AUTOSAR XML (schema 4-3-0)
package /MICROSAR/WdgM_swc/DataTypes
  5 x impl type, all with category=TYPE_REFERENCE:
    WdgM_SupervisedEntityIdType: range raw 0..65535, implementation-data-type=uint16  # Identifier of a supervised entity
    WdgM_CheckpointIdType: range raw 0..65535, implementation-data-type=uint16  # Identifier of a checkpoint
    WdgM_ModeType: range raw 0..255, implementation-data-type=uint8  # Identifier of the Watchdog trigger mode
    WdgM_LocalStatusType: compu {0=WDGM_LOCAL_STATUS_OK, 1=WDGM_LOCAL_STATUS_FAILED, 2=WDGM_LOCAL_STATUS_EXPIRED, 4=WDGM_LOCAL_STATUS_DEACTIVATED}, implementation-data-type=uint8  # Local Monitoring Status of a supervised entity.
    WdgM_GlobalStatusType: compu {0=WDGM_GLOBAL_STATUS_OK, 1=WDGM_GLOBAL_STATUS_FAILED, 2=WDGM_GLOBAL_STATUS_EXPIRED, 3=WDGM_GLOBAL_STATUS_STOPPED, 4=WDGM_GLOBAL_STATUS_DEACTIVATED}, implementation-data-type=uint8  # Global Monitoring Status summarizes all local monitoring statuses of all supervised entities.
package /MICROSAR/WdgM_swc/Interfaces
  client server interface WdgM_AliveSupervision: is-service=true, service-kind=WATCH-DOG-MANAGER
    operation CheckpointReached: possible-error=WdgM_AliveSupervision/E_NOT_OK  # Indicates to the Watchdog Manager that a Checkpoint within a Supervised Entity has been reached.
    error E_NOT_OK: error-code=1
  client server interface WdgM_LocalStatus: is-service=true, service-kind=WATCH-DOG-MANAGER
    operation GetLocalStatus: possible-error=WdgM_LocalStatus/E_NOT_OK  # Returns the supervision status of a supervised entity.
      arg Status: type=WdgM_LocalStatusType, direction=OUT  # Supervision status of the given supervised entity.
    error E_NOT_OK: error-code=1
  client server interface WdgM_General: is-service=true, service-kind=WATCH-DOG-MANAGER
    8 x operation, all with possible-error=WdgM_General/E_NOT_OK:
      GetMode  # Returns the current mode of the Watchdog Manager.
        arg Mode: type=WdgM_ModeType, direction=OUT  # Current mode of the Watchdog Manager.
      GetGlobalStatus  # Returns the global supervision status of the Watchdog Manager.
        arg Status: type=WdgM_GlobalStatusType, direction=OUT  # Global supervision status of the Watchdog Manager.
      GetLocalStatus  # Returns the supervision status of a supervised entity.
        arg SEID: type=WdgM_SupervisedEntityIdType, direction=IN  # Identifier of the supervised entity whose supervision status shall be returned.
        arg Status: type=WdgM_LocalStatusType, direction=OUT  # Supervision status of the given supervised entity.
      PerformReset  # Instructs the Watchdog Manager to cause a watchdog reset.
      SetMode  # Requests a new trigger mode
        arg Mode: type=WdgM_ModeType, direction=IN  # Desired new trigger mode id.
        arg CallerID: type=uint16, direction=IN  # Module ID of the calling module.
      GetFirstExpiredSEID  # Returns the id of that supervised entity which first reached the status WDGM_LOCAL_STATUS_EXPIRED.
        arg SEID: type=WdgM_SupervisedEntityIdType, direction=OUT  # Pointer to a variable that stores the id of the supervised entity.
      ActivateSupervisionEntity  # Activates the supervision of the given supervised entity.
        arg SEID: type=WdgM_SupervisedEntityIdType, direction=IN  # Identifier of the supervised entity whose supervision shall be enabled.
      DeactivateSupervisionEntity  # Deactivates the supervision of the given supervised entity.
        arg SEID: type=WdgM_SupervisedEntityIdType, direction=IN  # Identifier of the supervised entity whose supervision shall be disenabled.
    error E_NOT_OK: error-code=1
package /MICROSAR/WdgM_swc/ComponentTypes
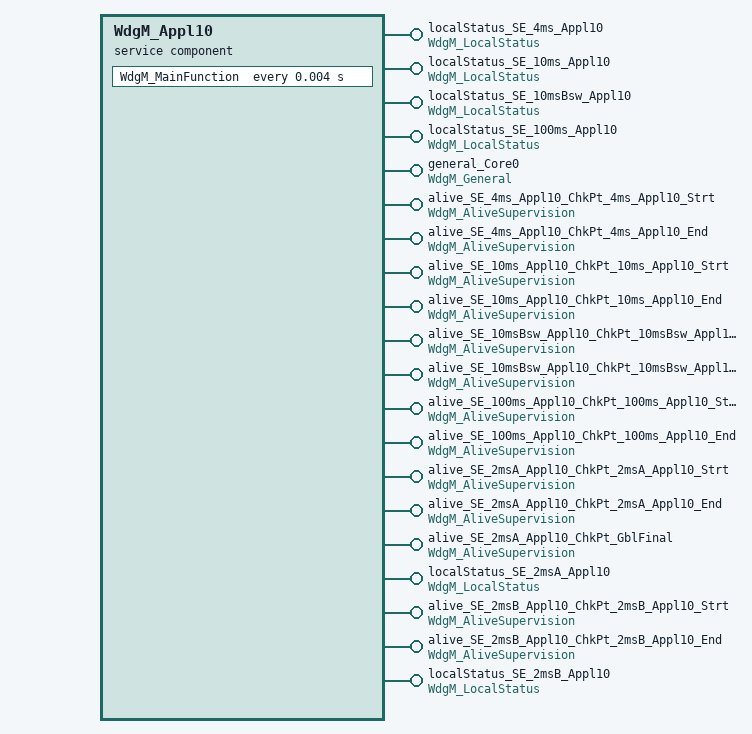
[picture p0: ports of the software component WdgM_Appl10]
  service sw component type WdgM_Appl10: category=SERVICE_COMPONENT
    20 x provide port:
      localStatus_SE_4ms_Appl10: provided-interface=WdgM_LocalStatus  # P-Port Prototype for supervised entity 'SE_4ms_Appl10' with Id '1' for Application 'Appl10' to request the local status.
      localStatus_SE_10ms_Appl10: provided-interface=WdgM_LocalStatus  # P-Port Prototype for supervised entity 'SE_10ms_Appl10' with Id '3' for Application 'Appl10' to request the local status.
      localStatus_SE_10msBsw_Appl10: provided-interface=WdgM_LocalStatus  # P-Port Prototype for supervised entity 'SE_10msBsw_Appl10' with Id '4' for Application 'Appl10' to request the local status.
      localStatus_SE_100ms_Appl10: provided-interface=WdgM_LocalStatus  # P-Port Prototype for supervised entity 'SE_100ms_Appl10' with Id '5' for Application 'Appl10' to request the local status.
      general_Core0: provided-interface=WdgM_General  # General P-Port-Prototype for core 0 (Appl10)
      alive_SE_4ms_Appl10_ChkPt_4ms_Appl10_Strt: provided-interface=WdgM_AliveSupervision  # Alive-P-Port Prototype for supervised entity 'SE_4ms_Appl10' with Id '1' for Application 'Appl10'.
      alive_SE_4ms_Appl10_ChkPt_4ms_Appl10_End: provided-interface=WdgM_AliveSupervision  # Alive-P-Port Prototype for supervised entity 'SE_4ms_Appl10' with Id '1' for Application 'Appl10'.
      alive_SE_10ms_Appl10_ChkPt_10ms_Appl10_Strt: provided-interface=WdgM_AliveSupervision  # Alive-P-Port Prototype for supervised entity 'SE_10ms_Appl10' with Id '3' for Application 'Appl10'.
      alive_SE_10ms_Appl10_ChkPt_10ms_Appl10_End: provided-interface=WdgM_AliveSupervision  # Alive-P-Port Prototype for supervised entity 'SE_10ms_Appl10' with Id '3' for Application 'Appl10'.
      alive_SE_10msBsw_Appl10_ChkPt_10msBsw_Appl10_Strt: provided-interface=WdgM_AliveSupervision  # Alive-P-Port Prototype for supervised entity 'SE_10msBsw_Appl10' with Id '4' for Application 'Appl10'.
      alive_SE_10msBsw_Appl10_ChkPt_10msBsw_Appl10_End: provided-interface=WdgM_AliveSupervision  # Alive-P-Port Prototype for supervised entity 'SE_10msBsw_Appl10' with Id '4' for Application 'Appl10'.
      alive_SE_100ms_Appl10_ChkPt_100ms_Appl10_Strt: provided-interface=WdgM_AliveSupervision  # Alive-P-Port Prototype for supervised entity 'SE_100ms_Appl10' with Id '5' for Application 'Appl10'.
      alive_SE_100ms_Appl10_ChkPt_100ms_Appl10_End: provided-interface=WdgM_AliveSupervision  # Alive-P-Port Prototype for supervised entity 'SE_100ms_Appl10' with Id '5' for Application 'Appl10'.
      alive_SE_2msA_Appl10_ChkPt_2msA_Appl10_Strt: provided-interface=WdgM_AliveSupervision  # Alive-P-Port Prototype for supervised entity 'SE_2msA_Appl10' with Id '0' for Application 'Appl10'.
      alive_SE_2msA_Appl10_ChkPt_2msA_Appl10_End: provided-interface=WdgM_AliveSupervision  # Alive-P-Port Prototype for supervised entity 'SE_2msA_Appl10' with Id '0' for Application 'Appl10'.
      alive_SE_2msA_Appl10_ChkPt_GblFinal: provided-interface=WdgM_AliveSupervision  # Alive-P-Port Prototype for supervised entity 'SE_2msA_Appl10' with Id '0' for Application 'Appl10'.
      localStatus_SE_2msA_Appl10: provided-interface=WdgM_LocalStatus  # P-Port Prototype for supervised entity 'SE_2msA_Appl10' with Id '0' for Application 'Appl10' to request the local status.
      alive_SE_2msB_Appl10_ChkPt_2msB_Appl10_Strt: provided-interface=WdgM_AliveSupervision  # Alive-P-Port Prototype for supervised entity 'SE_2msB_Appl10' with Id '0' for Application 'Appl10'.
      alive_SE_2msB_Appl10_ChkPt_2msB_Appl10_End: provided-interface=WdgM_AliveSupervision  # Alive-P-Port Prototype for supervised entity 'SE_2msB_Appl10' with Id '0' for Application 'Appl10'.
      localStatus_SE_2msB_Appl10: provided-interface=WdgM_LocalStatus  # P-Port Prototype for supervised entity 'SE_2msB_Appl10' with Id '0' for Application 'Appl10' to request the local status.
    behavior WdgM_Appl10InternalBehavior: handle-termination-and-restart=NO-SUPPORT
      timing event Timer_WdgM_MainFunction: start-on-event=WdgM_MainFunction, period=0.004
      27 x operation invoked event:
        OpEventGetLocalStatus_GetLocalStatus_localStatus_SE_4ms_Appl10: start-on-event=WdgM_Appl10InternalBehavior/GetLocalStatus, operation=localStatus_SE_4ms_Appl10.GetLocalStatus
        OpEventGetLocalStatus_GetLocalStatus_localStatus_SE_10ms_Appl10: start-on-event=WdgM_Appl10InternalBehavior/GetLocalStatus, operation=localStatus_SE_10ms_Appl10.GetLocalStatus
        OpEventGetLocalStatus_GetLocalStatus_localStatus_SE_10msBsw_Appl10: start-on-event=WdgM_Appl10InternalBehavior/GetLocalStatus, operation=localStatus_SE_10msBsw_Appl10.GetLocalStatus
        OpEventGetLocalStatus_GetLocalStatus_localStatus_SE_100ms_Appl10: start-on-event=WdgM_Appl10InternalBehavior/GetLocalStatus, operation=localStatus_SE_100ms_Appl10.GetLocalStatus
        OpEventGetLocalStatus_GetLocalStatus_general_Core0: start-on-event=WdgM_Appl10InternalBehavior/GetLocalStatus, operation=general_Core0.GetLocalStatus
        OpEventGetMode_GetMode_general_Core0: start-on-event=GetMode, operation=general_Core0.GetMode
        OpEventGetGlobalStatus_GetGlobalStatus_general_Core0: start-on-event=GetGlobalStatus, operation=general_Core0.GetGlobalStatus
        OpEventPerformReset_PerformReset_general_Core0: start-on-event=PerformReset, operation=general_Core0.PerformReset
        OpEventSetMode_SetMode_general_Core0: start-on-event=SetMode, operation=general_Core0.SetMode
        OpEventGetFirstExpiredSEID_GetFirstExpiredSEID_general_Core0: start-on-event=GetFirstExpiredSEID, operation=general_Core0.GetFirstExpiredSEID
        OpEventCheckpointReached_CheckpointReached_alive_SE_4ms_Appl10_ChkPt_4ms_Appl10_Strt: start-on-event=WdgM_Appl10InternalBehavior/CheckpointReached, operation=alive_SE_4ms_Appl10_ChkPt_4ms_Appl10_Strt.CheckpointReached
        OpEventCheckpointReached_CheckpointReached_alive_SE_4ms_Appl10_ChkPt_4ms_Appl10_End: start-on-event=WdgM_Appl10InternalBehavior/CheckpointReached, operation=alive_SE_4ms_Appl10_ChkPt_4ms_Appl10_End.CheckpointReached
        OpEventCheckpointReached_CheckpointReached_alive_SE_10ms_Appl10_ChkPt_10ms_Appl10_Strt: start-on-event=WdgM_Appl10InternalBehavior/CheckpointReached, operation=alive_SE_10ms_Appl10_ChkPt_10ms_Appl10_Strt.CheckpointReached
        OpEventCheckpointReached_CheckpointReached_alive_SE_10ms_Appl10_ChkPt_10ms_Appl10_End: start-on-event=WdgM_Appl10InternalBehavior/CheckpointReached, operation=alive_SE_10ms_Appl10_ChkPt_10ms_Appl10_End.CheckpointReached
        OpEventCheckpointReached_CheckpointReached_alive_SE_10msBsw_Appl10_ChkPt_10msBsw_Appl10_Strt: start-on-event=WdgM_Appl10InternalBehavior/CheckpointReached, operation=alive_SE_10msBsw_Appl10_ChkPt_10msBsw_Appl10_Strt.CheckpointReached
        OpEventCheckpointReached_CheckpointReached_alive_SE_10msBsw_Appl10_ChkPt_10msBsw_Appl10_End: start-on-event=WdgM_Appl10InternalBehavior/CheckpointReached, operation=alive_SE_10msBsw_Appl10_ChkPt_10msBsw_Appl10_End.CheckpointReached
        OpEventCheckpointReached_CheckpointReached_alive_SE_100ms_Appl10_ChkPt_100ms_Appl10_Strt: start-on-event=WdgM_Appl10InternalBehavior/CheckpointReached, operation=alive_SE_100ms_Appl10_ChkPt_100ms_Appl10_Strt.CheckpointReached
        OpEventCheckpointReached_CheckpointReached_alive_SE_100ms_Appl10_ChkPt_100ms_Appl10_End: start-on-event=WdgM_Appl10InternalBehavior/CheckpointReached, operation=alive_SE_100ms_Appl10_ChkPt_100ms_Appl10_End.CheckpointReached
        OpEventCheckpointReached_CheckpointReached_alive_SE_2msA_Appl10_ChkPt_2msA_Appl10_Strt: start-on-event=WdgM_Appl10InternalBehavior/CheckpointReached, operation=alive_SE_2msA_Appl10_ChkPt_2msA_Appl10_Strt.CheckpointReached
        OpEventCheckpointReached_CheckpointReached_alive_SE_2msA_Appl10_ChkPt_2msA_Appl10_End: start-on-event=WdgM_Appl10InternalBehavior/CheckpointReached, operation=alive_SE_2msA_Appl10_ChkPt_2msA_Appl10_End.CheckpointReached
        OpEventCheckpointReached_CheckpointReached_alive_SE_2msA_Appl10_ChkPt_GblFinal: start-on-event=WdgM_Appl10InternalBehavior/CheckpointReached, operation=alive_SE_2msA_Appl10_ChkPt_GblFinal.CheckpointReached
        OpEventGetLocalStatus_GetLocalStatus_localStatus_SE_2msA_Appl10: start-on-event=WdgM_Appl10InternalBehavior/GetLocalStatus, operation=localStatus_SE_2msA_Appl10.GetLocalStatus
        OpEventCheckpointReached_CheckpointReached_alive_SE_2msB_Appl10_ChkPt_2msB_Appl10_Strt: start-on-event=WdgM_Appl10InternalBehavior/CheckpointReached, operation=alive_SE_2msB_Appl10_ChkPt_2msB_Appl10_Strt.CheckpointReached
        OpEventCheckpointReached_CheckpointReached_alive_SE_2msB_Appl10_ChkPt_2msB_Appl10_End: start-on-event=WdgM_Appl10InternalBehavior/CheckpointReached, operation=alive_SE_2msB_Appl10_ChkPt_2msB_Appl10_End.CheckpointReached
        OpEventGetLocalStatus_GetLocalStatus_localStatus_SE_2msB_Appl10: start-on-event=WdgM_Appl10InternalBehavior/GetLocalStatus, operation=localStatus_SE_2msB_Appl10.GetLocalStatus
        OpEventActivateSupervisionEntity_ActivateSupervisionEntity_general_Core0: start-on-event=ActivateSupervisionEntity, operation=general_Core0.ActivateSupervisionEntity
        OpEventDeactivateSupervisionEntity_DeactivateSupervisionEntity_general_Core0: start-on-event=DeactivateSupervisionEntity, operation=general_Core0.DeactivateSupervisionEntity
      port-api-options:
        {enable-take-address=true, indirect-api=false, port-defined-argument-value{value=1, value-type=WdgM_SupervisedEntityIdType}, port=localStatus_SE_4ms_Appl10}
        {enable-take-address=true, indirect-api=false, port-defined-argument-value{value=3, value-type=WdgM_SupervisedEntityIdType}, port=localStatus_SE_10ms_Appl10}
        {enable-take-address=true, indirect-api=false, port-defined-argument-value{value=4, value-type=WdgM_SupervisedEntityIdType}, port=localStatus_SE_10msBsw_Appl10}
        enable-take-address=true, indirect-api=false, port=general_Core0
        {enable-take-address=true, indirect-api=false, port-arg-values=[{value=SEID:1, value-type=WdgM_SupervisedEntityIdType}, {value=CPID:0, value-type=WdgM_CheckpointIdType}], port=alive_SE_4ms_Appl10_ChkPt_4ms_Appl10_Strt}
        {enable-take-address=true, indirect-api=false, port-arg-values=[{value=SEID:1, value-type=WdgM_SupervisedEntityIdType}, {value=CPID:1, value-type=WdgM_CheckpointIdType}], port=alive_SE_4ms_Appl10_ChkPt_4ms_Appl10_End}
        {enable-take-address=true, indirect-api=false, port-arg-values=[{value=SEID:3, value-type=WdgM_SupervisedEntityIdType}, {value=CPID:0, value-type=WdgM_CheckpointIdType}], port=alive_SE_10ms_Appl10_ChkPt_10ms_Appl10_Strt}
        {enable-take-address=true, indirect-api=false, port-arg-values=[{value=SEID:3, value-type=WdgM_SupervisedEntityIdType}, {value=CPID:1, value-type=WdgM_CheckpointIdType}], port=alive_SE_10ms_Appl10_ChkPt_10ms_Appl10_End}
        {enable-take-address=true, indirect-api=false, port-arg-values=[{value=SEID:4, value-type=WdgM_SupervisedEntityIdType}, {value=CPID:0, value-type=WdgM_CheckpointIdType}], port=alive_SE_10msBsw_Appl10_ChkPt_10msBsw_Appl10_Strt}
        {enable-take-address=true, indirect-api=false, port-arg-values=[{value=SEID:4, value-type=WdgM_SupervisedEntityIdType}, {value=CPID:1, value-type=WdgM_CheckpointIdType}], port=alive_SE_10msBsw_Appl10_ChkPt_10msBsw_Appl10_End}
        {enable-take-address=true, indirect-api=false, port-arg-values=[{value=SEID:2, value-type=WdgM_SupervisedEntityIdType}, {value=CPID:0, value-type=WdgM_CheckpointIdType}], port=alive_SE_100ms_Appl10_ChkPt_100ms_Appl10_Strt}
        {enable-take-address=true, indirect-api=false, port-arg-values=[{value=SEID:2, value-type=WdgM_SupervisedEntityIdType}, {value=CPID:1, value-type=WdgM_CheckpointIdType}], port=alive_SE_100ms_Appl10_ChkPt_100ms_Appl10_End}
        {enable-take-address=true, indirect-api=false, port-defined-argument-value{value=2, value-type=WdgM_SupervisedEntityIdType}, port=localStatus_SE_100ms_Appl10}
        {enable-take-address=true, indirect-api=false, port-arg-values=[{value=SEID:0, value-type=WdgM_SupervisedEntityIdType}, {value=CPID:0, value-type=WdgM_CheckpointIdType}], port=alive_SE_2msA_Appl10_ChkPt_2msA_Appl10_Strt}
        {enable-take-address=true, indirect-api=false, port-arg-values=[{value=SEID:0, value-type=WdgM_SupervisedEntityIdType}, {value=CPID:1, value-type=WdgM_CheckpointIdType}], port=alive_SE_2msA_Appl10_ChkPt_2msA_Appl10_End}
        {enable-take-address=true, indirect-api=false, port-arg-values=[{value=SEID:0, value-type=WdgM_SupervisedEntityIdType}, {value=CPID:2, value-type=WdgM_CheckpointIdType}], port=alive_SE_2msA_Appl10_ChkPt_GblFinal}
        {enable-take-address=true, indirect-api=false, port-defined-argument-value{value=0, value-type=WdgM_SupervisedEntityIdType}, port=localStatus_SE_2msA_Appl10}
        {enable-take-address=true, indirect-api=false, port-arg-values=[{value=SEID:14, value-type=WdgM_SupervisedEntityIdType}, {value=CPID:0, value-type=WdgM_CheckpointIdType}], port=alive_SE_2msB_Appl10_ChkPt_2msB_Appl10_Strt}
        {enable-take-address=true, indirect-api=false, port-arg-values=[{value=SEID:14, value-type=WdgM_SupervisedEntityIdType}, {value=CPID:1, value-type=WdgM_CheckpointIdType}], port=alive_SE_2msB_Appl10_ChkPt_2msB_Appl10_End}
        {enable-take-address=true, indirect-api=false, port-defined-argument-value{value=14, value-type=WdgM_SupervisedEntityIdType}, port=localStatus_SE_2msB_Appl10}
      10 x runnable, all with can-be-invoked-concurrently=true:
        CheckpointReached: symbol=WdgM_CheckpointReached
        GetLocalStatus: symbol=WdgM_GetLocalStatus
        WdgM_MainFunction
        GetMode: symbol=WdgM_GetMode
        GetGlobalStatus: symbol=WdgM_GetGlobalStatus
        PerformReset: symbol=WdgM_PerformReset
        SetMode: symbol=WdgM_SetMode
        GetFirstExpiredSEID: symbol=WdgM_GetFirstExpiredSEID
        ActivateSupervisionEntity: symbol=WdgM_ActivateSupervisionEntity
        DeactivateSupervisionEntity: symbol=WdgM_DeactivateSupervisionEntity
  swc implementation WdgM_Appl10Implementation: programming-language=C, behavior=WdgM_Appl10InternalBehavior
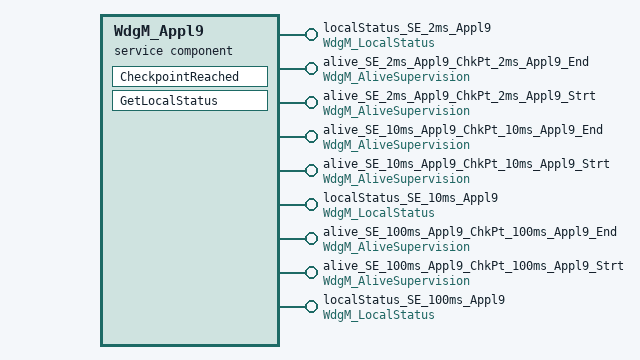
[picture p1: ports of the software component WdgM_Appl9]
  service sw component type WdgM_Appl9: category=SERVICE_COMPONENT
    9 x provide port:
      localStatus_SE_2ms_Appl9: provided-interface=WdgM_LocalStatus  # P-Port Prototype for supervised entity 'SE_2ms_Appl9' with Id '5' for Application 'Appl9' to request the local status.
      alive_SE_2ms_Appl9_ChkPt_2ms_Appl9_End: provided-interface=WdgM_AliveSupervision  # Alive-P-Port Prototype for supervised entity 'SE_2ms_Appl9' with Id '5' for Application 'Appl9'.
      alive_SE_2ms_Appl9_ChkPt_2ms_Appl9_Strt: provided-interface=WdgM_AliveSupervision  # Alive-P-Port Prototype for supervised entity 'SE_2ms_Appl9' with Id '5' for Application 'Appl9'.
      alive_SE_10ms_Appl9_ChkPt_10ms_Appl9_End: provided-interface=WdgM_AliveSupervision  # Alive-P-Port Prototype for supervised entity 'SE_10ms_Appl9' with Id '6' for Application 'Appl9'.
      alive_SE_10ms_Appl9_ChkPt_10ms_Appl9_Strt: provided-interface=WdgM_AliveSupervision  # Alive-P-Port Prototype for supervised entity 'SE_10ms_Appl9' with Id '6' for Application 'Appl9'.
      localStatus_SE_10ms_Appl9: provided-interface=WdgM_LocalStatus  # P-Port Prototype for supervised entity 'SE_10ms_Appl9' with Id '6' for Application 'Appl9' to request the local status.
      alive_SE_100ms_Appl9_ChkPt_100ms_Appl9_End: provided-interface=WdgM_AliveSupervision  # Alive-P-Port Prototype for supervised entity 'SE_100ms_Appl9' with Id '7' for Application 'Appl9'.
      alive_SE_100ms_Appl9_ChkPt_100ms_Appl9_Strt: provided-interface=WdgM_AliveSupervision  # Alive-P-Port Prototype for supervised entity 'SE_100ms_Appl9' with Id '7' for Application 'Appl9'.
      localStatus_SE_100ms_Appl9: provided-interface=WdgM_LocalStatus  # P-Port Prototype for supervised entity 'SE_100ms_Appl9' with Id '7' for Application 'Appl9' to request the local status.
    behavior WdgM_Appl9InternalBehavior: handle-termination-and-restart=NO-SUPPORT
      9 x operation invoked event:
        OpEventGetLocalStatus_GetLocalStatus_localStatus_SE_2ms_Appl9: start-on-event=WdgM_Appl9InternalBehavior/GetLocalStatus, operation=localStatus_SE_2ms_Appl9.GetLocalStatus
        OpEventCheckpointReached_CheckpointReached_alive_SE_2ms_Appl9_ChkPt_2ms_Appl9_End: start-on-event=WdgM_Appl9InternalBehavior/CheckpointReached, operation=alive_SE_2ms_Appl9_ChkPt_2ms_Appl9_End.CheckpointReached
        OpEventCheckpointReached_CheckpointReached_alive_SE_2ms_Appl9_ChkPt_2ms_Appl9_Strt: start-on-event=WdgM_Appl9InternalBehavior/CheckpointReached, operation=alive_SE_2ms_Appl9_ChkPt_2ms_Appl9_Strt.CheckpointReached
        OpEventCheckpointReached_CheckpointReached_alive_SE_10ms_Appl9_ChkPt_10ms_Appl9_End: start-on-event=WdgM_Appl9InternalBehavior/CheckpointReached, operation=alive_SE_10ms_Appl9_ChkPt_10ms_Appl9_End.CheckpointReached
        OpEventCheckpointReached_CheckpointReached_alive_SE_10ms_Appl9_ChkPt_10ms_Appl9_Strt: start-on-event=WdgM_Appl9InternalBehavior/CheckpointReached, operation=alive_SE_10ms_Appl9_ChkPt_10ms_Appl9_Strt.CheckpointReached
        OpEventGetLocalStatus_GetLocalStatus_localStatus_SE_10ms_Appl9: start-on-event=WdgM_Appl9InternalBehavior/GetLocalStatus, operation=localStatus_SE_10ms_Appl9.GetLocalStatus
        OpEventCheckpointReached_CheckpointReached_alive_SE_100ms_Appl9_ChkPt_100ms_Appl9_End: start-on-event=WdgM_Appl9InternalBehavior/CheckpointReached, operation=alive_SE_100ms_Appl9_ChkPt_100ms_Appl9_End.CheckpointReached
        OpEventCheckpointReached_CheckpointReached_alive_SE_100ms_Appl9_ChkPt_100ms_Appl9_Strt: start-on-event=WdgM_Appl9InternalBehavior/CheckpointReached, operation=alive_SE_100ms_Appl9_ChkPt_100ms_Appl9_Strt.CheckpointReached
        OpEventGetLocalStatus_GetLocalStatus_localStatus_SE_100ms_Appl9: start-on-event=WdgM_Appl9InternalBehavior/GetLocalStatus, operation=localStatus_SE_100ms_Appl9.GetLocalStatus
      port-api-options:
        {enable-take-address=true, indirect-api=false, port-defined-argument-value{value=5, value-type=WdgM_SupervisedEntityIdType}, port=localStatus_SE_2ms_Appl9}
        {enable-take-address=true, indirect-api=false, port-defined-argument-value{value=6, value-type=WdgM_SupervisedEntityIdType}, port=localStatus_SE_10ms_Appl9}
        {enable-take-address=true, indirect-api=false, port-defined-argument-value{value=7, value-type=WdgM_SupervisedEntityIdType}, port=localStatus_SE_100ms_Appl9}
        {enable-take-address=true, indirect-api=false, port-arg-values=[{value=SEID:5, value-type=WdgM_SupervisedEntityIdType}, {value=CPID:1, value-type=WdgM_CheckpointIdType}], port=alive_SE_2ms_Appl9_ChkPt_2ms_Appl9_End}
        {enable-take-address=true, indirect-api=false, port-arg-values=[{value=SEID:5, value-type=WdgM_SupervisedEntityIdType}, {value=CPID:0, value-type=WdgM_CheckpointIdType}], port=alive_SE_2ms_Appl9_ChkPt_2ms_Appl9_Strt}
        {enable-take-address=true, indirect-api=false, port-arg-values=[{value=SEID:6, value-type=WdgM_SupervisedEntityIdType}, {value=CPID:1, value-type=WdgM_CheckpointIdType}], port=alive_SE_10ms_Appl9_ChkPt_10ms_Appl9_End}
        {enable-take-address=true, indirect-api=false, port-arg-values=[{value=SEID:6, value-type=WdgM_SupervisedEntityIdType}, {value=CPID:0, value-type=WdgM_CheckpointIdType}], port=alive_SE_10ms_Appl9_ChkPt_10ms_Appl9_Strt}
        {enable-take-address=true, indirect-api=false, port-arg-values=[{value=SEID:7, value-type=WdgM_SupervisedEntityIdType}, {value=CPID:1, value-type=WdgM_CheckpointIdType}], port=alive_SE_100ms_Appl9_ChkPt_100ms_Appl9_End}
        {enable-take-address=true, indirect-api=false, port-arg-values=[{value=SEID:7, value-type=WdgM_SupervisedEntityIdType}, {value=CPID:0, value-type=WdgM_CheckpointIdType}], port=alive_SE_100ms_Appl9_ChkPt_100ms_Appl9_Strt}
      runnable CheckpointReached: can-be-invoked-concurrently=true, symbol=WdgM_CheckpointReached
      runnable GetLocalStatus: can-be-invoked-concurrently=true, symbol=WdgM_GetLocalStatus
  swc implementation WdgM_Appl9Implementation: programming-language=C, behavior=WdgM_Appl9InternalBehavior
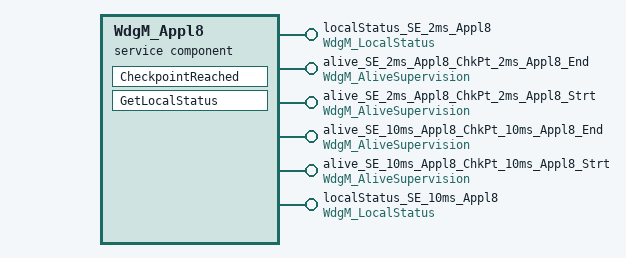
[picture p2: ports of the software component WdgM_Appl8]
  service sw component type WdgM_Appl8: category=SERVICE_COMPONENT
    6 x provide port:
      localStatus_SE_2ms_Appl8: provided-interface=WdgM_LocalStatus  # P-Port Prototype for supervised entity 'SE_2ms_Appl8' with Id '8' for Application 'Appl8' to request the local status.
      alive_SE_2ms_Appl8_ChkPt_2ms_Appl8_End: provided-interface=WdgM_AliveSupervision  # Alive-P-Port Prototype for supervised entity 'SE_2ms_Appl8' with Id '8' for Application 'Appl8'.
      alive_SE_2ms_Appl8_ChkPt_2ms_Appl8_Strt: provided-interface=WdgM_AliveSupervision  # Alive-P-Port Prototype for supervised entity 'SE_2ms_Appl8' with Id '8' for Application 'Appl8'.
      alive_SE_10ms_Appl8_ChkPt_10ms_Appl8_End: provided-interface=WdgM_AliveSupervision  # Alive-P-Port Prototype for supervised entity 'SE_10ms_Appl8' with Id '9' for Application 'Appl8'.
      alive_SE_10ms_Appl8_ChkPt_10ms_Appl8_Strt: provided-interface=WdgM_AliveSupervision  # Alive-P-Port Prototype for supervised entity 'SE_10ms_Appl8' with Id '9' for Application 'Appl8'.
      localStatus_SE_10ms_Appl8: provided-interface=WdgM_LocalStatus  # P-Port Prototype for supervised entity 'SE_10ms_Appl8' with Id '9' for Application 'Appl8' to request the local status.
    behavior WdgM_Appl8InternalBehavior: handle-termination-and-restart=NO-SUPPORT
      6 x operation invoked event:
        OpEventGetLocalStatus_GetLocalStatus_localStatus_SE_2ms_Appl8: start-on-event=WdgM_Appl8InternalBehavior/GetLocalStatus, operation=localStatus_SE_2ms_Appl8.GetLocalStatus
        OpEventCheckpointReached_CheckpointReached_alive_SE_2ms_Appl8_ChkPt_2ms_Appl8_End: start-on-event=WdgM_Appl8InternalBehavior/CheckpointReached, operation=alive_SE_2ms_Appl8_ChkPt_2ms_Appl8_End.CheckpointReached
        OpEventCheckpointReached_CheckpointReached_alive_SE_2ms_Appl8_ChkPt_2ms_Appl8_Strt: start-on-event=WdgM_Appl8InternalBehavior/CheckpointReached, operation=alive_SE_2ms_Appl8_ChkPt_2ms_Appl8_Strt.CheckpointReached
        OpEventCheckpointReached_CheckpointReached_alive_SE_10ms_Appl8_ChkPt_10ms_Appl8_End: start-on-event=WdgM_Appl8InternalBehavior/CheckpointReached, operation=alive_SE_10ms_Appl8_ChkPt_10ms_Appl8_End.CheckpointReached
        OpEventCheckpointReached_CheckpointReached_alive_SE_10ms_Appl8_ChkPt_10ms_Appl8_Strt: start-on-event=WdgM_Appl8InternalBehavior/CheckpointReached, operation=alive_SE_10ms_Appl8_ChkPt_10ms_Appl8_Strt.CheckpointReached
        OpEventGetLocalStatus_GetLocalStatus_localStatus_SE_10ms_Appl8: start-on-event=WdgM_Appl8InternalBehavior/GetLocalStatus, operation=localStatus_SE_10ms_Appl8.GetLocalStatus
      port-api-options:
        {enable-take-address=true, indirect-api=false, port-defined-argument-value{value=8, value-type=WdgM_SupervisedEntityIdType}, port=localStatus_SE_2ms_Appl8}
        {enable-take-address=true, indirect-api=false, port-defined-argument-value{value=9, value-type=WdgM_SupervisedEntityIdType}, port=localStatus_SE_10ms_Appl8}
        {enable-take-address=true, indirect-api=false, port-arg-values=[{value=SEID:8, value-type=WdgM_SupervisedEntityIdType}, {value=CPID:1, value-type=WdgM_CheckpointIdType}], port=alive_SE_2ms_Appl8_ChkPt_2ms_Appl8_End}
        {enable-take-address=true, indirect-api=false, port-arg-values=[{value=SEID:8, value-type=WdgM_SupervisedEntityIdType}, {value=CPID:0, value-type=WdgM_CheckpointIdType}], port=alive_SE_2ms_Appl8_ChkPt_2ms_Appl8_Strt}
        {enable-take-address=true, indirect-api=false, port-arg-values=[{value=SEID:9, value-type=WdgM_SupervisedEntityIdType}, {value=CPID:1, value-type=WdgM_CheckpointIdType}], port=alive_SE_10ms_Appl8_ChkPt_10ms_Appl8_End}
        {enable-take-address=true, indirect-api=false, port-arg-values=[{value=SEID:9, value-type=WdgM_SupervisedEntityIdType}, {value=CPID:0, value-type=WdgM_CheckpointIdType}], port=alive_SE_10ms_Appl8_ChkPt_10ms_Appl8_Strt}
      runnable CheckpointReached: can-be-invoked-concurrently=true, symbol=WdgM_CheckpointReached
      runnable GetLocalStatus: can-be-invoked-concurrently=true, symbol=WdgM_GetLocalStatus
  swc implementation WdgM_Appl8Implementation: programming-language=C, behavior=WdgM_Appl8InternalBehavior
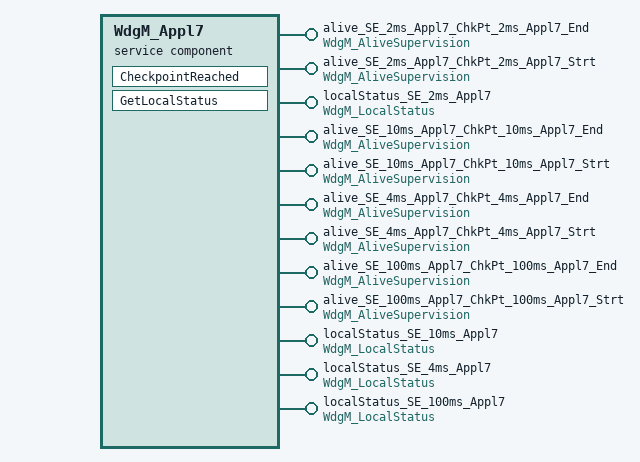
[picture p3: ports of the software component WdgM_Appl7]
  service sw component type WdgM_Appl7: category=SERVICE_COMPONENT
    12 x provide port:
      alive_SE_2ms_Appl7_ChkPt_2ms_Appl7_End: provided-interface=WdgM_AliveSupervision  # Alive-P-Port Prototype for supervised entity 'SE_2ms_Appl7' with Id '10' for Application 'Appl7'.
      alive_SE_2ms_Appl7_ChkPt_2ms_Appl7_Strt: provided-interface=WdgM_AliveSupervision  # Alive-P-Port Prototype for supervised entity 'SE_2ms_Appl7' with Id '10' for Application 'Appl7'.
      localStatus_SE_2ms_Appl7: provided-interface=WdgM_LocalStatus  # P-Port Prototype for supervised entity 'SE_2ms_Appl7' with Id '10' for Application 'Appl7' to request the local status.
      alive_SE_10ms_Appl7_ChkPt_10ms_Appl7_End: provided-interface=WdgM_AliveSupervision  # Alive-P-Port Prototype for supervised entity 'SE_10ms_Appl7' with Id '11' for Application 'Appl7'.
      alive_SE_10ms_Appl7_ChkPt_10ms_Appl7_Strt: provided-interface=WdgM_AliveSupervision  # Alive-P-Port Prototype for supervised entity 'SE_10ms_Appl7' with Id '11' for Application 'Appl7'.
      alive_SE_4ms_Appl7_ChkPt_4ms_Appl7_End: provided-interface=WdgM_AliveSupervision  # Alive-P-Port Prototype for supervised entity 'SE_4ms_Appl7' with Id '12' for Application 'Appl7'.
      alive_SE_4ms_Appl7_ChkPt_4ms_Appl7_Strt: provided-interface=WdgM_AliveSupervision  # Alive-P-Port Prototype for supervised entity 'SE_4ms_Appl7' with Id '12' for Application 'Appl7'.
      alive_SE_100ms_Appl7_ChkPt_100ms_Appl7_End: provided-interface=WdgM_AliveSupervision  # Alive-P-Port Prototype for supervised entity 'SE_100ms_Appl7' with Id '13' for Application 'Appl7'.
      alive_SE_100ms_Appl7_ChkPt_100ms_Appl7_Strt: provided-interface=WdgM_AliveSupervision  # Alive-P-Port Prototype for supervised entity 'SE_100ms_Appl7' with Id '13' for Application 'Appl7'.
      localStatus_SE_10ms_Appl7: provided-interface=WdgM_LocalStatus  # P-Port Prototype for supervised entity 'SE_10ms_Appl7' with Id '11' for Application 'Appl7' to request the local status.
      localStatus_SE_4ms_Appl7: provided-interface=WdgM_LocalStatus  # P-Port Prototype for supervised entity 'SE_4ms_Appl7' with Id '12' for Application 'Appl7' to request the local status.
      localStatus_SE_100ms_Appl7: provided-interface=WdgM_LocalStatus  # P-Port Prototype for supervised entity 'SE_100ms_Appl7' with Id '13' for Application 'Appl7' to request the local status.
    behavior WdgM_Appl7InternalBehavior: handle-termination-and-restart=NO-SUPPORT
      12 x operation invoked event:
        OpEventCheckpointReached_CheckpointReached_alive_SE_2ms_Appl7_ChkPt_2ms_Appl7_End: start-on-event=WdgM_Appl7InternalBehavior/CheckpointReached, operation=alive_SE_2ms_Appl7_ChkPt_2ms_Appl7_End.CheckpointReached
        OpEventCheckpointReached_CheckpointReached_alive_SE_2ms_Appl7_ChkPt_2ms_Appl7_Strt: start-on-event=WdgM_Appl7InternalBehavior/CheckpointReached, operation=alive_SE_2ms_Appl7_ChkPt_2ms_Appl7_Strt.CheckpointReached
        OpEventGetLocalStatus_GetLocalStatus_localStatus_SE_2ms_Appl7: start-on-event=WdgM_Appl7InternalBehavior/GetLocalStatus, operation=localStatus_SE_2ms_Appl7.GetLocalStatus
        OpEventCheckpointReached_CheckpointReached_alive_SE_10ms_Appl7_ChkPt_10ms_Appl7_End: start-on-event=WdgM_Appl7InternalBehavior/CheckpointReached, operation=alive_SE_10ms_Appl7_ChkPt_10ms_Appl7_End.CheckpointReached
        OpEventCheckpointReached_CheckpointReached_alive_SE_10ms_Appl7_ChkPt_10ms_Appl7_Strt: start-on-event=WdgM_Appl7InternalBehavior/CheckpointReached, operation=alive_SE_10ms_Appl7_ChkPt_10ms_Appl7_Strt.CheckpointReached
        OpEventCheckpointReached_CheckpointReached_alive_SE_4ms_Appl7_ChkPt_4ms_Appl7_End: start-on-event=WdgM_Appl7InternalBehavior/CheckpointReached, operation=alive_SE_4ms_Appl7_ChkPt_4ms_Appl7_End.CheckpointReached
        OpEventCheckpointReached_CheckpointReached_alive_SE_4ms_Appl7_ChkPt_4ms_Appl7_Strt: start-on-event=WdgM_Appl7InternalBehavior/CheckpointReached, operation=alive_SE_4ms_Appl7_ChkPt_4ms_Appl7_Strt.CheckpointReached
        OpEventCheckpointReached_CheckpointReached_alive_SE_100ms_Appl7_ChkPt_100ms_Appl7_End: start-on-event=WdgM_Appl7InternalBehavior/CheckpointReached, operation=alive_SE_100ms_Appl7_ChkPt_100ms_Appl7_End.CheckpointReached
        OpEventCheckpointReached_CheckpointReached_alive_SE_100ms_Appl7_ChkPt_100ms_Appl7_Strt: start-on-event=WdgM_Appl7InternalBehavior/CheckpointReached, operation=alive_SE_100ms_Appl7_ChkPt_100ms_Appl7_Strt.CheckpointReached
        OpEventGetLocalStatus_GetLocalStatus_localStatus_SE_10ms_Appl7: start-on-event=WdgM_Appl7InternalBehavior/GetLocalStatus, operation=localStatus_SE_10ms_Appl7.GetLocalStatus
        OpEventGetLocalStatus_GetLocalStatus_localStatus_SE_4ms_Appl7: start-on-event=WdgM_Appl7InternalBehavior/GetLocalStatus, operation=localStatus_SE_4ms_Appl7.GetLocalStatus
        OpEventGetLocalStatus_GetLocalStatus_localStatus_SE_100ms_Appl7: start-on-event=WdgM_Appl7InternalBehavior/GetLocalStatus, operation=localStatus_SE_100ms_Appl7.GetLocalStatus
      port-api-options:
        {enable-take-address=true, indirect-api=false, port-defined-argument-value{value=10, value-type=WdgM_SupervisedEntityIdType}, port=localStatus_SE_2ms_Appl7}
        {enable-take-address=true, indirect-api=false, port-defined-argument-value{value=11, value-type=WdgM_SupervisedEntityIdType}, port=localStatus_SE_10ms_Appl7}
        {enable-take-address=true, indirect-api=false, port-defined-argument-value{value=12, value-type=WdgM_SupervisedEntityIdType}, port=localStatus_SE_4ms_Appl7}
        {enable-take-address=true, indirect-api=false, port-defined-argument-value{value=13, value-type=WdgM_SupervisedEntityIdType}, port=localStatus_SE_100ms_Appl7}
        {enable-take-address=true, indirect-api=false, port-arg-values=[{value=SEID:10, value-type=WdgM_SupervisedEntityIdType}, {value=CPID:1, value-type=WdgM_CheckpointIdType}], port=alive_SE_2ms_Appl7_ChkPt_2ms_Appl7_End}
        {enable-take-address=true, indirect-api=false, port-arg-values=[{value=SEID:10, value-type=WdgM_SupervisedEntityIdType}, {value=CPID:0, value-type=WdgM_CheckpointIdType}], port=alive_SE_2ms_Appl7_ChkPt_2ms_Appl7_Strt}
        {enable-take-address=true, indirect-api=false, port-arg-values=[{value=SEID:11, value-type=WdgM_SupervisedEntityIdType}, {value=CPID:1, value-type=WdgM_CheckpointIdType}], port=alive_SE_10ms_Appl7_ChkPt_10ms_Appl7_End}
        {enable-take-address=true, indirect-api=false, port-arg-values=[{value=SEID:11, value-type=WdgM_SupervisedEntityIdType}, {value=CPID:0, value-type=WdgM_CheckpointIdType}], port=alive_SE_10ms_Appl7_ChkPt_10ms_Appl7_Strt}
        {enable-take-address=true, indirect-api=false, port-arg-values=[{value=SEID:12, value-type=WdgM_SupervisedEntityIdType}, {value=CPID:1, value-type=WdgM_CheckpointIdType}], port=alive_SE_4ms_Appl7_ChkPt_4ms_Appl7_End}
        {enable-take-address=true, indirect-api=false, port-arg-values=[{value=SEID:12, value-type=WdgM_SupervisedEntityIdType}, {value=CPID:0, value-type=WdgM_CheckpointIdType}], port=alive_SE_4ms_Appl7_ChkPt_4ms_Appl7_Strt}
        {enable-take-address=true, indirect-api=false, port-arg-values=[{value=SEID:13, value-type=WdgM_SupervisedEntityIdType}, {value=CPID:1, value-type=WdgM_CheckpointIdType}], port=alive_SE_100ms_Appl7_ChkPt_100ms_Appl7_End}
        {enable-take-address=true, indirect-api=false, port-arg-values=[{value=SEID:13, value-type=WdgM_SupervisedEntityIdType}, {value=CPID:0, value-type=WdgM_CheckpointIdType}], port=alive_SE_100ms_Appl7_ChkPt_100ms_Appl7_Strt}
      runnable CheckpointReached: can-be-invoked-concurrently=true, symbol=WdgM_CheckpointReached
      runnable GetLocalStatus: can-be-invoked-concurrently=true, symbol=WdgM_GetLocalStatus
  swc implementation WdgM_Appl7Implementation: programming-language=C, behavior=WdgM_Appl7InternalBehavior
